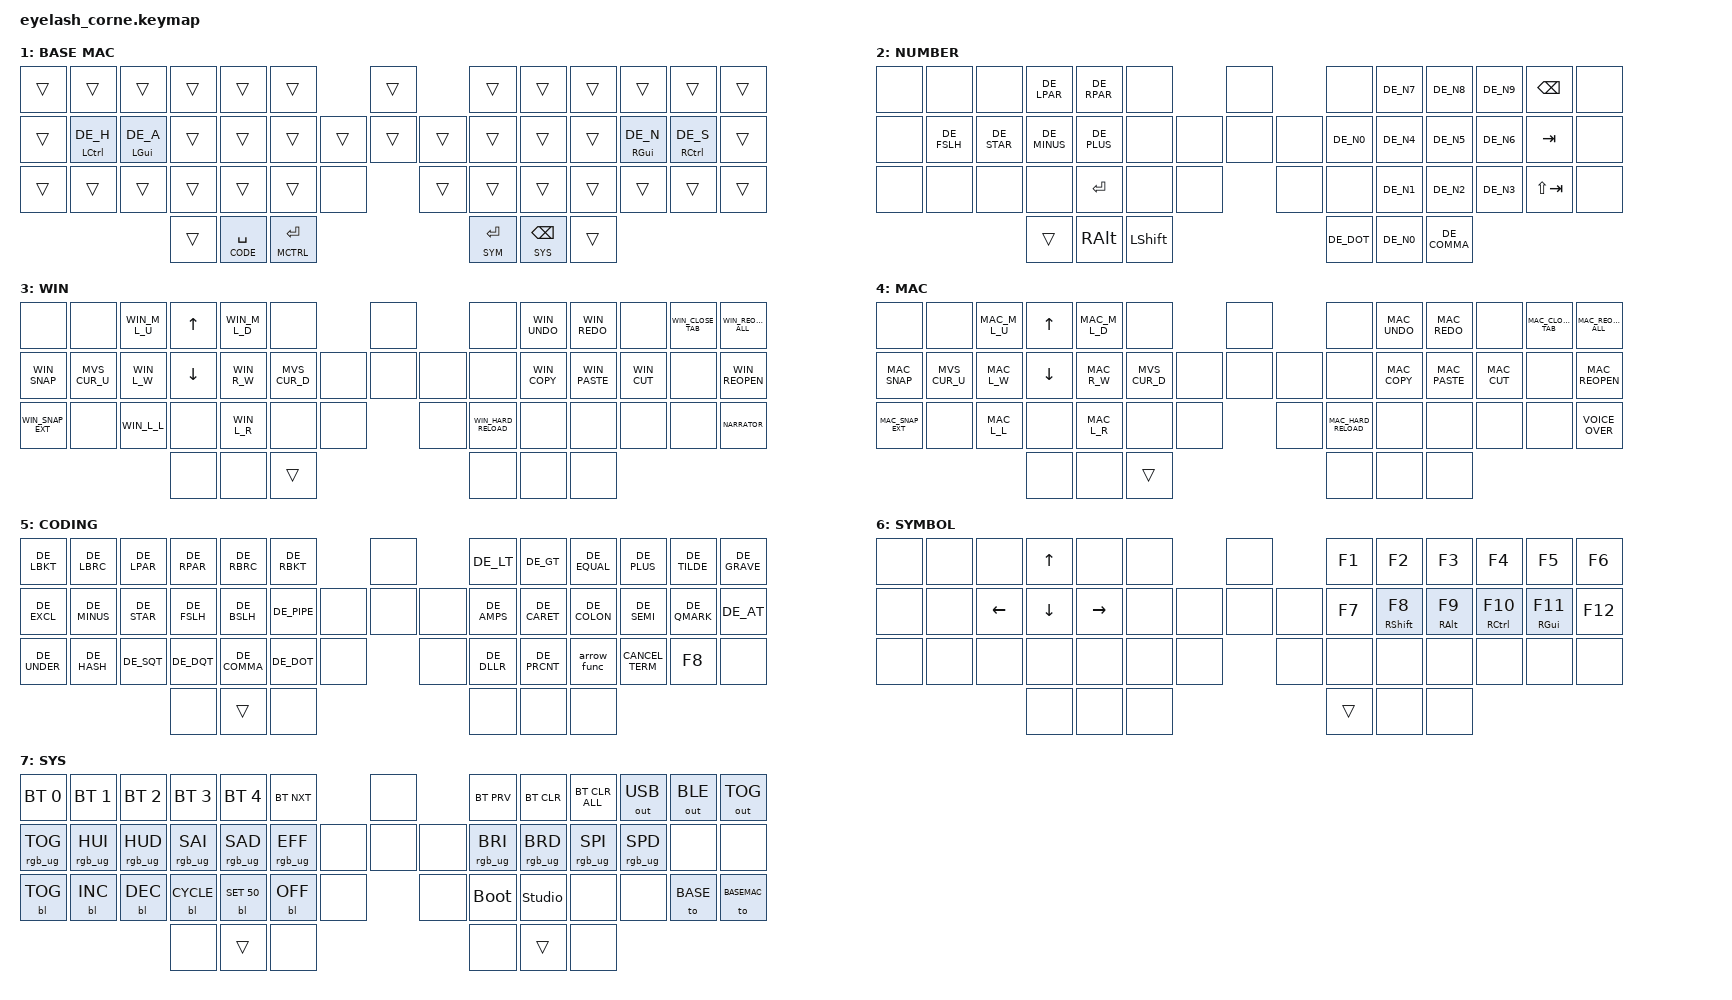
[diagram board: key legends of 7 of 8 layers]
#include "includes/eyelash_42.h"
#include <behaviors.dtsi>
#include <dt-bindings/zmk/backlight.h>
#include <dt-bindings/zmk/keys.h>
#include <locale/keys_de.h>
#include <dt-bindings/zmk/outputs.h>
#include <dt-bindings/zmk/bt.h>



#define BASE 0 // Base Layer for Win
#define BASEMAC 1 // Layer Shifter to Mac specific
#define NUM 2
#define WCTRL 3
#define MCTRL 4
#define CODE 5
#define SYM 6
#define SYS 7

#define ADAPT 17

// #define XXX &none
// #define ___ &trans

#include "includes/mouse.dtsi"
#include "includes/bluetooth.dtsi"
#include "includes/rgb.dtsi"

#include "includes/behaviours_homerow_mods.dtsi"
#include "includes/custom_behaviours.dtsi"
#include "includes/encoders.dtsi"

#include "includes/custom_keycodes.dtsi"
#include "includes/custom_mac_short.dtsi"
#include "includes/custom_win_short.dtsi"


&soft_off { hold-time-ms = <2000>; };


/* ───────────────────────────── Behaviors ───────────────────────────── */

/ {
    behaviors {
        /* Bestehend: Shift/Caps Tap-Dance */

        td0: td0 {
            compatible = "zmk,behavior-tap-dance";
            display-name = "Shift/Caps Lock Tap Dance";
            #binding-cells = <0>;
            bindings = <&kp LEFT_SHIFT>, <&kp CAPS>;
        };
      

        /* Media tap-dances (aus deiner dtsi, falls genutzt) */

        tap_ct: tap_ct {
            compatible = "zmk,behavior-tap-dance";
            #binding-cells = <0>;
            tapping-term-ms = <200>;
            bindings = <&kp LCTRL>, <&kp LEFT_ALT>;
        };

        tap_mu: tap_mu {
            compatible = "zmk,behavior-tap-dance";
            #binding-cells = <0>;
            tapping-term-ms = <200>;
            bindings = <&kp C_NEXT>, <&kp C_PREV>;
        };  

        tilde_de: tilde_de {
            compatible = "zmk,behavior-macro";
            #binding-cells = <0>;
            label = "TILDE_DE";
            bindings = <&kp RA(RBKT)>;               /* AltGr + +  → ~ */
        };

        
    };

    /* ───────────────────────── Encoder / Combos ───────────────────────── */

    

    combos {
        compatible = "zmk,combos";

        /*softoff {
            bindings = <&soft_off>;
            key-positions = <1 15 29>;
        };*/
        /* (optional) deine frühere layer_3 Combo:
       combo_layer_3 {
         timeout-ms = <25>;
         bindings = <&tog 3>;
         key-positions = <0 1>;
         layers = <0xff>;
       };
    */
    };

    /* ───────────────────────────── Keymap ───────────────────────────── */

    macros {
    };

    keymap {
        compatible = "zmk,keymap";

        /* ================= BASE (Deutsch + ergonomisch) ================= */
        // ----------------------------------------------------------------------------------------------------
        // | Esc |  X  |  .  |  O  |  ,  |  Y  |                |  G  |     |  V  |  G   |  C  |  L  |  J  |  ß  |h
        // | Tab |  H  |  A  |  E  |  I  |  U  |          |  G  |  G  |  G  |  D  |  T   |  R  |  N  |  S  |  F  |
        // |  #  |  K  |  Q  |  Ä  |  Ü  |  Ö  |  #  |          |  G  |     |  B  |  P   |  W  |  M  |  Z  | DEL |
        //                   | DEL | SPC | ENT |                            | ENT | SPC  | ALT |

        default_layer {
            display-name = "BASE";
            bindings = <
// ╭────────────────────────┬────────────────────────┬────────────────────────┬────────────────────────┬────────────────────────┬────────────────────────╮                                        ╭────────────────────────╮                             ╭────────────────────────┬────────────────────────┬────────────────────────┬───────────────────────┬────────────────────────┬────────────────────────╮
             &kp ESC           &kp DE_X                 &kp DE_DOT                 &kp DE_O                &kp DE_COMMA                &kp DE_Y                                                           R_COL_W                                            &kp DE_V                 &kp DE_G                 &kp DE_C                 &kp DE_L                &kp DE_J                 &kp DE_SZ           
// ├────────────────────────┼────────────────────────┼────────────────────────┼────────────────────────┼────────────────────────┼────────────────────────┤               ╭────────────────────────┼────────────────────────┼────────────────────────╮    ├────────────────────────┼────────────────────────┼────────────────────────┼───────────────────────┼────────────────────────┼────────────────────────┤
             &kp TAB           &hm_l LGUI DE_H          &hm_l LCTRL DE_A           &hm_l LALT DE_E         &hm_l LSHFT DE_I            &kp DE_U                                  &win_active              R_RGB_TOG               &mac_active                &kp DE_D                 &hm_r RSHFT DE_T         &hm_r RALT DE_R          &hm_r RCTRL DE_N        &hm_r RGUI DE_S          &kp DE_F            
// ├────────────────────────┼────────────────────────┼────────────────────────┼────────────────────────┼────────────────────────┼────────────────────────┤  ╭───────╮    ╰────────────────────────┼────────────────────────┼────────────────────────╯    ├────────────────────────┼────────────────────────┼────────────────────────┼───────────────────────┼────────────────────────┼────────────────────────┤
             &kp LC(DE_C)      &kp DE_K                 &kp DE_Q                   &kp DE_A_UMLAUT         &kp DE_U_UMLAUT             &kp DE_O_UMLAUT        &none                                       R_COL_G                                            &kp DE_B                 &kp DE_P                 &kp DE_W                 &kp DE_M                &kp DE_Z                 &kp DEL        
// ╰────────────────────────┴────────────────────────┴────────────────────────┴────────────────────────┼────────────────────────┼────────────────────────┤  ╰───────╯                             ╰────────────────────────╯                             ├────────────────────────┼────────────────────────┼────────────────────────┼───────────────────────┼────────────────────────┼────────────────────────╯
                                                                                   &lt NUM DEL             &lt CODE SPACE              &lt WCTRL ENTER                                                                                                       &lt SYM ENTER            &lt SYS BACKSPACE        &kp RSHIFT      
//                                                                            ╰────────────────────────┴────────────────────────┴────────────────────────╯                                                                                               ╰────────────────────────┴────────────────────────┴────────────────────────╯
            >;
            sensor-bindings = <&scroll_encoder>;
        };

        /* ================= BASE MAC (Deutsch + ergonomisch) ================= */
        // ----------------------------------------------------------------------------------------------------
        // | Esc |  X  |  .  |  O  |  ,  |  Y  |                |  G  |     |  V  |  G   |  C  |  L  |  J  |  ß  |
        // | Tab |  H  |  A  |  E  |  I  |  U  |          |  G  |  G  |  G  |  D  |  T   |  R  |  N  |  S  |  F  |
        // |  #  |  K  |  Q  |  Ä  |  Ü  |  Ö  |  #  |          |  G  |     |  B  |  P   |  W  |  M  |  Z  | DEL |
        //                   | DEL | SPC | ENT |                            | ENT | SPC  | ALT |

        defaultmac_layer {
            display-name = "BASE MAC";
            bindings = <
// ╭────────────────────────┬────────────────────────┬────────────────────────┬────────────────────────┬────────────────────────┬────────────────────────╮                                        ╭────────────────────────╮                             ╭────────────────────────┬────────────────────────┬────────────────────────┬───────────────────────┬────────────────────────┬────────────────────────╮
            &trans                    &trans                   &trans                   &trans                   &trans                    &trans                                                           &trans                                                 &trans                    &trans                    &trans                  &trans                   &trans                  &trans         
// ├────────────────────────┼────────────────────────┼────────────────────────┼────────────────────────┼────────────────────────┼────────────────────────┤               ╭────────────────────────┼────────────────────────┼────────────────────────╮    ├────────────────────────┼────────────────────────┼────────────────────────┼───────────────────────┼────────────────────────┼────────────────────────┤
            &trans               &hm_l LCTRL DE_H         &hm_l LGUI DE_A               &trans                   &trans                    &trans                                  &trans                   &trans                   &trans                        &trans                    &trans                    &trans           &hm_r RGUI DE_N        &hm_r RCTRL DE_S                 &trans         
// ├────────────────────────┼────────────────────────┼────────────────────────┼────────────────────────┼────────────────────────┼────────────────────────┤  ╭───────╮    ╰────────────────────────┼────────────────────────┼────────────────────────╯    ├────────────────────────┼────────────────────────┼────────────────────────┼───────────────────────┼────────────────────────┼────────────────────────┤
            &trans                    &trans                   &trans                   &trans                   &trans                    &trans             &none                                         &trans                                                 &trans                    &trans                    &trans                  &trans                   &trans                  &trans         
// ╰────────────────────────┴────────────────────────┴────────────────────────┴────────────────────────┼────────────────────────┼────────────────────────┤  ╰───────╯                             ╰────────────────────────╯                             ├────────────────────────┼────────────────────────┼────────────────────────┼───────────────────────┼────────────────────────┼────────────────────────╯
                                                                                        &trans             &lt CODE SPACE             &lt MCTRL ENTER                                                                                                            &lt SYM ENTER         &lt SYS BACKSPACE               &trans        
//                                                                            ╰────────────────────────┴────────────────────────┴────────────────────────╯                                                                                               ╰────────────────────────┴────────────────────────┴────────────────────────╯
            >;
            sensor-bindings = <&scroll_encoder>;
        };

        /* ================= NUMBER ================= */
        // ----------------------------------------------------------------------------------------------------
        // |     |     |     |     |     |     |                |  G  |     |     |  7  |  8  |  9  | BSP  |     |
        // |     |  /  |  *  |  -  |  +  |     |          |  G  |  G  |  G  |     |  4  |  5  |  6  | TAB  |     |
        // |     |     |     |     | ENT |     |  #  |          |  G  |     |  0  |  1  |  2  |  3  | RTAB |     |
        //                   |     |     |     |                            |     |     |  0  |

        num_layer {
            display-name = "NUMBER";
            bindings = <
// ╭────────────────────────┬────────────────────────┬────────────────────────┬────────────────────────┬────────────────────────┬────────────────────────╮                                        ╭────────────────────────╮                             ╭────────────────────────┬────────────────────────┬────────────────────────┬───────────────────────┬────────────────────────┬────────────────────────╮
            &none                     &none                    &none                 &kp DE_LPAR              &kp DE_RPAR                  &none                                                            &none                                                  &none                 &kp DE_N7                  &kp DE_N8                &kp DE_N9              &kp BSPC                   &none          
// ├────────────────────────┼────────────────────────┼────────────────────────┼────────────────────────┼────────────────────────┼────────────────────────┤               ╭────────────────────────┼────────────────────────┼────────────────────────╮    ├────────────────────────┼────────────────────────┼────────────────────────┼───────────────────────┼────────────────────────┼────────────────────────┤
            &none                &kp DE_FSLH                &kp DE_STAR              &kp DE_MINUS             &kp DE_PLUS                  &none                                   &none                    &none                    &none                       &kp DE_N0               &kp DE_N4                  &kp DE_N5                &kp DE_N6              &kp TAB                    &none          
// ├────────────────────────┼────────────────────────┼────────────────────────┼────────────────────────┼────────────────────────┼────────────────────────┤  ╭───────╮    ╰────────────────────────┼────────────────────────┼────────────────────────╯    ├────────────────────────┼────────────────────────┼────────────────────────┼───────────────────────┼────────────────────────┼────────────────────────┤
            &none                     &none                    &none                    &none                 &kp ENTER                    &none              &none                                         &none                                                  &none                 &kp DE_N1                  &kp DE_N2                &kp DE_N3              &kp LS(TAB)                &none          
// ╰────────────────────────┴────────────────────────┴────────────────────────┴────────────────────────┼────────────────────────┼────────────────────────┤  ╰───────╯                             ╰────────────────────────╯                             ├────────────────────────┼────────────────────────┼────────────────────────┼───────────────────────┼────────────────────────┼────────────────────────╯
                                                                                        &trans                &kp RALT                  &kp LSHFT                                                                                                               &kp DE_DOT               &kp DE_N0                  &kp DE_COMMA                        
//                                                                            ╰────────────────────────┴────────────────────────┴────────────────────────╯                                                                                               ╰────────────────────────┴────────────────────────┴────────────────────────╯
            >;
            sensor-bindings = <&scroll_encoder>;
        };

        winshort_layer {
            display-name = "WIN";
            bindings = <
// ╭────────────────────────┬────────────────────────┬────────────────────────┬────────────────────────┬────────────────────────┬────────────────────────╮                                        ╭────────────────────────╮                             ╭────────────────────────┬────────────────────────┬────────────────────────┬───────────────────────┬────────────────────────┬────────────────────────╮
            &none                     &none               &kp WIN_M_L_U               &kp UP                 &kp WIN_M_L_D                 &none                                                            &none                                                  &none                &kp WIN_UNDO             &kp WIN_REDO                  &none            &kp WIN_CLOSE_TAB          &kp WIN_REOPEN_ALL  
// ├────────────────────────┼────────────────────────┼────────────────────────┼────────────────────────┼────────────────────────┼────────────────────────┤               ╭────────────────────────┼────────────────────────┼────────────────────────╮    ├────────────────────────┼────────────────────────┼────────────────────────┼───────────────────────┼────────────────────────┼────────────────────────┤
         &kp WIN_SNAP            &kp MVS_CUR_U            &kp WIN_L_W                 &kp DOWN               &kp WIN_R_W             &kp MVS_CUR_D                                 &none                    &none                    &none                         &none                &kp WIN_COPY             &kp WIN_PASTE              &kp WIN_CUT                 &none              &kp WIN_REOPEN      
// ├────────────────────────┼────────────────────────┼────────────────────────┼────────────────────────┼────────────────────────┼────────────────────────┤  ╭───────╮    ╰────────────────────────┼────────────────────────┼────────────────────────╯    ├────────────────────────┼────────────────────────┼────────────────────────┼───────────────────────┼────────────────────────┼────────────────────────┤
         &kp WIN_SNAP_EXT             &none               &kp WIN_L_L                   &none                &kp WIN_L_R                   &none              &none                                         &none                                           &kp WIN_HARD_RELOAD              &none                     &none                   &none                    &none              &kp NARRATOR      
// ╰────────────────────────┴────────────────────────┴────────────────────────┴────────────────────────┼────────────────────────┼────────────────────────┤  ╰───────╯                             ╰────────────────────────╯                             ├────────────────────────┼────────────────────────┼────────────────────────┼───────────────────────┼────────────────────────┼────────────────────────╯
                                                                                        &none                    &none                     &trans                                                                                                                  &none                     &none                     &none         
//                                                                            ╰────────────────────────┴────────────────────────┴────────────────────────╯                                                                                               ╰────────────────────────┴────────────────────────┴────────────────────────╯
            >;
            sensor-bindings = <&scroll_encoder>;
        };

        macshort_layer {
            display-name = "MAC";
            bindings = <
// ╭────────────────────────┬────────────────────────┬────────────────────────┬────────────────────────┬────────────────────────┬────────────────────────╮                                        ╭────────────────────────╮                             ╭────────────────────────┬────────────────────────┬────────────────────────┬───────────────────────┬────────────────────────┬────────────────────────╮
            &none                     &none               &kp MAC_M_L_U               &kp UP                 &kp MAC_M_L_D                 &none                                                            &none                                                  &none                &kp MAC_UNDO             &kp MAC_REDO                  &none            &kp MAC_CLOSE_TAB          &kp MAC_REOPEN_ALL           
// ├────────────────────────┼────────────────────────┼────────────────────────┼────────────────────────┼────────────────────────┼────────────────────────┤               ╭────────────────────────┼────────────────────────┼────────────────────────╮    ├────────────────────────┼────────────────────────┼────────────────────────┼───────────────────────┼────────────────────────┼────────────────────────┤
         &kp MAC_SNAP            &kp MVS_CUR_U            &kp MAC_L_W                 &kp DOWN               &kp MAC_R_W             &kp MVS_CUR_D                                 &none                    &none                    &none                         &none                &kp MAC_COPY             &kp MAC_PASTE              &kp MAC_CUT                 &none              &kp MAC_REOPEN           
// ├────────────────────────┼────────────────────────┼────────────────────────┼────────────────────────┼────────────────────────┼────────────────────────┤  ╭───────╮    ╰────────────────────────┼────────────────────────┼────────────────────────╯    ├────────────────────────┼────────────────────────┼────────────────────────┼───────────────────────┼────────────────────────┼────────────────────────┤
         &kp MAC_SNAP_EXT             &none               &kp MAC_L_L                   &none                &kp MAC_L_R                   &none              &none                                         &none                                           &kp MAC_HARD_RELOAD              &none                     &none                   &none                    &none              &kp VOICE_OVER           
// ╰────────────────────────┴────────────────────────┴────────────────────────┴────────────────────────┼────────────────────────┼────────────────────────┤  ╰───────╯                             ╰────────────────────────╯                             ├────────────────────────┼────────────────────────┼────────────────────────┼───────────────────────┼────────────────────────┼────────────────────────╯
                                                                                        &none                    &none                     &trans                                                                                                                  &none                     &none                     &none         
//                                                                            ╰────────────────────────┴────────────────────────┴────────────────────────╯                                                                                               ╰────────────────────────┴────────────────────────┴────────────────────────╯
            >;
            sensor-bindings = <&scroll_encoder>;

        };

        /* ================= CODING ================= */
        // ----------------------------------------------------------------------------------------------------
        // |  [  |  {  |  (  |  )  |  }  |  ]  |                |  G  |     |  <  |  >  |  =  |  +  |  ~  |  `  |
        // |  !  |  -  |  *  |  /  |  \  |  |  |          |  G  |  G  |  G  |  &  |  ^  |  :  |  ;  |  ?  |  @  |
        // |  _  |  #  |  '  |  "  |  ,  |  .  |  #  |          |  G  |     |  $  |  %  |  => |  ^C |  F8 |     |
        //                   |     |     |     |                            |     |     |     |

        code_layer {
            display-name = "CODING";
            bindings = <
// ╭────────────────────────┬────────────────────────┬────────────────────────┬────────────────────────┬────────────────────────┬────────────────────────╮                                        ╭────────────────────────╮                             ╭────────────────────────┬────────────────────────┬────────────────────────┬───────────────────────┬────────────────────────┬────────────────────────╮
         &kp DE_LBKT              &kp DE_LBRC             &kp DE_LPAR              &kp DE_RPAR               &kp DE_RBRC              &kp DE_RBKT                                                           &none                                               &kp DE_LT                &kp DE_GT               &kp DE_EQUAL             &kp DE_PLUS             &kp DE_TILDE              &kp DE_GRAVE           
// ├────────────────────────┼────────────────────────┼────────────────────────┼────────────────────────┼────────────────────────┼────────────────────────┤               ╭────────────────────────┼────────────────────────┼────────────────────────╮    ├────────────────────────┼────────────────────────┼────────────────────────┼───────────────────────┼────────────────────────┼────────────────────────┤
         &kp DE_EXCL              &kp DE_MINUS            &kp DE_STAR              &kp DE_FSLH               &kp DE_BSLH              &kp DE_PIPE                                  &none                    &none                    &none                      &kp DE_AMPS              &kp DE_CARET            &kp DE_COLON             &kp DE_SEMI             &kp DE_QMARK              &kp DE_AT           
// ├────────────────────────┼────────────────────────┼────────────────────────┼────────────────────────┼────────────────────────┼────────────────────────┤  ╭───────╮    ╰────────────────────────┼────────────────────────┼────────────────────────╯    ├────────────────────────┼────────────────────────┼────────────────────────┼───────────────────────┼────────────────────────┼────────────────────────┤
         &kp DE_UNDER             &kp DE_HASH             &kp DE_SQT               &kp DE_DQT                &kp DE_COMMA             &kp DE_DOT              &none                                         &none                                               &kp DE_DLLR              &kp DE_PRCNT            &arrow_func              &kp CANCEL_TERM         &kp F8                       &none          
// ╰────────────────────────┴────────────────────────┴────────────────────────┴────────────────────────┼────────────────────────┼────────────────────────┤  ╰───────╯                             ╰────────────────────────╯                             ├────────────────────────┼────────────────────────┼────────────────────────┼───────────────────────┼────────────────────────┼────────────────────────╯
                                                                                        &none                     &trans                   &none                                                                                                                   &none                     &none                     &none         
//                                                                            ╰────────────────────────┴────────────────────────┴────────────────────────╯                                                                                               ╰────────────────────────┴────────────────────────┴────────────────────────╯
            >;
            sensor-bindings = <&scroll_encoder>;
        };

        /* ================= SYMBOL ================= */
        // ----------------------------------------------------------------------------------------------------
        // |     |     |     |     |     |     |                |  G  |     | F1  | F2  | F3  | F4  | F5  | F6  |
        // |     |     |     |     |     |     |          |  G  |  G  |  G  | F7  | F8  | F9  | F10 | F11 | F12 |
        // |     |     |     |     |     |     |  #  |          |  G  |     |     |     |     |     |     |     |
        //                   |     |     |     |                            |     |     |     |

        sym_layer {
            display-name = "SYMBOL";
            bindings = <
// ╭────────────────────────┬────────────────────────┬────────────────────────┬────────────────────────┬────────────────────────┬────────────────────────╮                                        ╭────────────────────────╮                             ╭────────────────────────┬────────────────────────┬────────────────────────┬───────────────────────┬────────────────────────┬────────────────────────╮
            &none                     &none                    &none                  &kp UP                     &none                     &none                                                            &none                                                 &kp F1                    &kp F2                    &kp F3                  &kp F4                   &kp F5                  &kp F6           
// ├────────────────────────┼────────────────────────┼────────────────────────┼────────────────────────┼────────────────────────┼────────────────────────┤               ╭────────────────────────┼────────────────────────┼────────────────────────╮    ├────────────────────────┼────────────────────────┼────────────────────────┼───────────────────────┼────────────────────────┼────────────────────────┤
            &none                     &none                  &kp LEFT                 &kp DOWN                 &kp RIGHT                   &none                                   &none                    &none                    &none                        &kp F7                &hm_r RSHFT F8            &hm_r RALT F9          &hm_r RCTRL F10        &hm_r RGUI F11                 &kp F12           
// ├────────────────────────┼────────────────────────┼────────────────────────┼────────────────────────┼────────────────────────┼────────────────────────┤  ╭───────╮    ╰────────────────────────┼────────────────────────┼────────────────────────╯    ├────────────────────────┼────────────────────────┼────────────────────────┼───────────────────────┼────────────────────────┼────────────────────────┤
            &none                     &none                    &none                    &none                    &none                     &none              &none                                         &none                                                  &none                     &none                     &none                   &none                    &none                   &none          
// ╰────────────────────────┴────────────────────────┴────────────────────────┴────────────────────────┼────────────────────────┼────────────────────────┤  ╰───────╯                             ╰────────────────────────╯                             ├────────────────────────┼────────────────────────┼────────────────────────┼───────────────────────┼────────────────────────┼────────────────────────╯
                                                                                        &none                    &none                     &none                                                                                                                   &trans                    &none                     &none         
//                                                                            ╰────────────────────────┴────────────────────────┴────────────────────────╯                                                                                               ╰────────────────────────┴────────────────────────┴────────────────────────╯
            >;
            sensor-bindings = <&scroll_encoder>;
        };

        /* ================= SYS ================= */
        // ----------------------------------------------------------------------------------------------------
        // |     |     |     |     |     |     |                |  G  |     |     |     |     |     |     |     |
        // |     |     |     |     |     |     |          |  G  |  G  |  G  |     |     |     |     |     |     |
        // |     |     |     |     |     |     |  #  |          |  G  |     |     |     |     |     |     |     |
        //                   |     |     |     |                            |     |     |     |

        sys_layer {
            display-name = "SYS";
            bindings = <
// ╭────────────────────────┬────────────────────────┬────────────────────────┬────────────────────────┬────────────────────────┬────────────────────────╮                                        ╭────────────────────────╮                             ╭────────────────────────┬────────────────────────┬────────────────────────┬───────────────────────┬────────────────────────┬────────────────────────╮
         &bt BT_SEL 0              &bt BT_SEL 1            &bt BT_SEL 2             &bt BT_SEL 3             &bt BT_SEL 4              &bt BT_NXT                                                           &none                                              &bt BT_PRV               &bt BT_CLR               &bt BT_CLR_ALL           &out OUT_USB            &out OUT_BLE             &out OUT_TOG       
// ├────────────────────────┼────────────────────────┼────────────────────────┼────────────────────────┼────────────────────────┼────────────────────────┤               ╭────────────────────────┼────────────────────────┼────────────────────────╮    ├────────────────────────┼────────────────────────┼────────────────────────┼───────────────────────┼────────────────────────┼────────────────────────┤
         &rgb_ug RGB_TOG           &rgb_ug RGB_HUI         &rgb_ug RGB_HUD          &rgb_ug RGB_SAI          &rgb_ug RGB_SAD           &rgb_ug RGB_EFF                             &none                    &none                    &none                     &rgb_ug RGB_BRI          &rgb_ug RGB_BRD          &rgb_ug RGB_SPI          &rgb_ug RGB_SPD              &none                   &none          
// ├────────────────────────┼────────────────────────┼────────────────────────┼────────────────────────┼────────────────────────┼────────────────────────┤  ╭───────╮    ╰────────────────────────┼────────────────────────┼────────────────────────╯    ├────────────────────────┼────────────────────────┼────────────────────────┼───────────────────────┼────────────────────────┼────────────────────────┤
         &bl BL_TOG                &bl BL_INC              &bl BL_DEC               &bl BL_CYCLE             &bl BL_SET 50             &bl BL_OFF             &none                                         &none                                              &bootloader              &studio_unlock                 &none                   &none              &to BASE                 &to BASEMAC        
// ╰────────────────────────┴────────────────────────┴────────────────────────┴────────────────────────┼────────────────────────┼────────────────────────┤  ╰───────╯                             ╰────────────────────────╯                             ├────────────────────────┼────────────────────────┼────────────────────────┼───────────────────────┼────────────────────────┼────────────────────────╯
                                                                                        &none                    &trans                    &none                                                                                                                   &none                     &trans                    &none         
//                                                                            ╰────────────────────────┴────────────────────────┴────────────────────────╯                                                                                               ╰────────────────────────┴────────────────────────┴────────────────────────╯
            >;
            sensor-bindings = <&scroll_encoder>;
        };
    };

};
